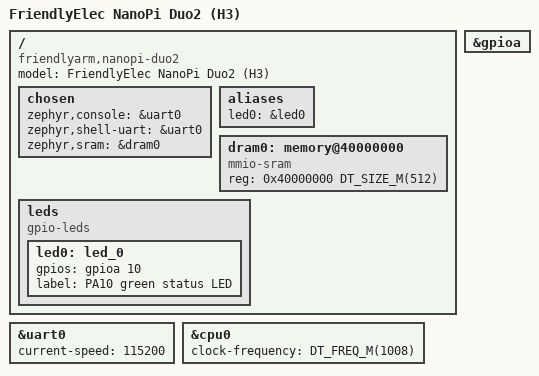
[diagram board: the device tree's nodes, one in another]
/*
 * FriendlyElec NanoPi Duo2 (H3) - out-of-tree board of 32_03_zephyr/ports. See README.md here.
 * SPDX-License-Identifier: Apache-2.0
 */

/dts-v1/;

#include <allwinner/sun8i-h3.dtsi>
#include <arm/allwinner/sun8i-h3-gpio.dtsi>
#include <zephyr/dt-bindings/gpio/gpio.h>

/ {
	model = "FriendlyElec NanoPi Duo2 (H3)";
	compatible = "friendlyarm,nanopi-duo2", "allwinner,sun8i-h3";

	chosen {
		zephyr,console = &uart0;
		zephyr,shell-uart = &uart0;
		zephyr,sram = &dram0;
	};

	aliases {
		led0 = &led0;
	};

	dram0: memory@40000000 {
		device_type = "memory";
		compatible = "mmio-sram";
		reg = <0x40000000 DT_SIZE_M(512)>;
	};

	leds {
		compatible = "gpio-leds";

		led0: led_0 {
			gpios = <&gpioa 10 GPIO_ACTIVE_HIGH>;
			label = "PA10 green status LED";
		};
	};
};

&uart0 {
	status = "okay";
	current-speed = <115200>;
};

&gpioa {
	status = "okay";
};

&cpu0 {
	clock-frequency = <DT_FREQ_M(1008)>;
};
